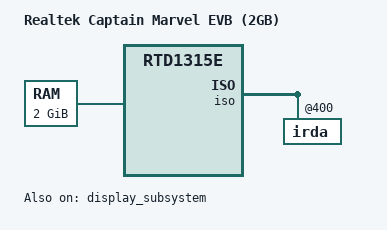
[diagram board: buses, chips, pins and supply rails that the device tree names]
// SPDX-License-Identifier: (GPL-2.0-or-later OR BSD-2-Clause)
/*
 * Copyright (c) 2022 Realtek Semiconductor Corp.
 */

/dts-v1/;

#include "rtd1315e-captainmarvel.dtsi"

/ {
	compatible = "realtek,captainmarvel", "realtek,rtd1315e";
	model = "Realtek Captain Marvel EVB (2GB)";

	memory@40000 {
		device_type = "memory";
		reg = <0x00040000 0x7ffc0000>; /* 2 GB */
	};
};

&display_subsystem {
        ports = <&vo_out_legacy>;
        status = "okay";
};

&iso {
        irda: irda@400 {
                hw,rc-map-name = "rc-realtek-sri";
        };
};

&irda {
        wakeup-key = <116>,<148>,<149>,<377>,<531>,<532>;
};
